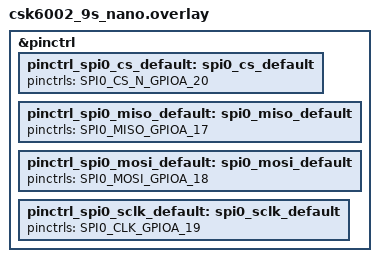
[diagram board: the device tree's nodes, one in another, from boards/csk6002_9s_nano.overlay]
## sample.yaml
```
tests:
  sample.board.csk6.driver.spi_master:
    platform_allow: csk6011a_nano
    tags: csk6
    harness: console
    timeout: 10
    harness_config:
      type: one_line
      regex:
        - "spi master sending data ..."
```

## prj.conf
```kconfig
CONFIG_GPIO=y
CONFIG_SPI=y
CONFIG_HEAP_MEM_POOL_SIZE=10240
CONFIG_LOG=y
```

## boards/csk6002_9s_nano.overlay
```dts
&pinctrl{
            /* SPIC alternate function */
            pinctrl_spi0_cs_default: spi0_cs_default{
                    pinctrls = <SPI0_CS_N_GPIOA_20>;
            };

            pinctrl_spi0_miso_default: spi0_miso_default{
                    pinctrls = <SPI0_MISO_GPIOA_17>;
            };

            pinctrl_spi0_mosi_default: spi0_mosi_default{
                    pinctrls = <SPI0_MOSI_GPIOA_18>;
            };

            pinctrl_spi0_sclk_default: spi0_sclk_default{
                    pinctrls = <SPI0_CLK_GPIOA_19>;
            };
            
};
```

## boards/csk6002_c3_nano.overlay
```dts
&csk6002_c3_nano_pinctrl{
            /* SPIC alternate function */
            pinctrl_spi0_cs_default: spi0_cs_default{
                    pinctrls = <SPI0_CS_N_GPIOA_20>;
            };

            pinctrl_spi0_miso_default: spi0_miso_default{
                    pinctrls = <SPI0_MISO_GPIOA_17>;
            };

            pinctrl_spi0_mosi_default: spi0_mosi_default{
                    pinctrls = <SPI0_MOSI_GPIOA_18>;
            };

            pinctrl_spi0_sclk_default: spi0_sclk_default{
                    pinctrls = <SPI0_CLK_GPIOA_19>;
            };
            
};
```

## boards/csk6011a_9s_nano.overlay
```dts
&csk6011a_9s_nano_pinctrl{
            /* SPIC alternate function */
            pinctrl_spi0_cs_default: spi0_cs_default{
                    pinctrls = <SPI0_CS_N_GPIOA_20>;
            };

            pinctrl_spi0_miso_default: spi0_miso_default{
                    pinctrls = <SPI0_MISO_GPIOA_17>;
            };

            pinctrl_spi0_mosi_default: spi0_mosi_default{
                    pinctrls = <SPI0_MOSI_GPIOA_18>;
            };

            pinctrl_spi0_sclk_default: spi0_sclk_default{
                    pinctrls = <SPI0_CLK_GPIOA_19>;
            };
            
};
```

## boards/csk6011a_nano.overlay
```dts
/*
 * Copyright (c) 2023 Anhui(Shenzhen) Listenai Co., Ltd.
 *
 * SPDX-License-Identifier: Apache-2.0
 */

&pinctrl {
	/* SPIC alternate function */
	pinctrl_spi0_cs_default: spi0_cs_default{
		pinctrls = <SPI0_CS_N_GPIOA_20>;
	};

	pinctrl_spi0_miso_default: spi0_miso_default{
		pinctrls = <SPI0_MISO_GPIOA_17>;
	};

	pinctrl_spi0_mosi_default: spi0_mosi_default{
		pinctrls = <SPI0_MOSI_GPIOA_18>;
	};

	pinctrl_spi0_sclk_default: spi0_sclk_default{
		pinctrls = <SPI0_CLK_GPIOA_19>;
	};

};
```

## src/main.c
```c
/*
 * Copyright (c) 2023 Anhui(Shenzhen) Listenai Co., Ltd.
 *
 * SPDX-License-Identifier: Apache-2.0
 */

#include <errno.h>
#include <string.h>

#include <device.h>
#include <drivers/spi.h>
#include <kernel.h>
#include <sys/printk.h>
#include <zephyr.h>

#define UINT8_MAX_NUM (0xff)

void main(void)
{
	printk("spi master example\n");
	const struct device *spi;
	spi = DEVICE_DT_GET(DT_NODELABEL(spi0));
	if (!device_is_ready(spi)) {
		printk("SPI device %s is not ready\n", spi->name);
		return;
	}

	struct spi_config spi_cfg = {0};
	/* spi master 8bit, LSB first*/
	spi_cfg.operation = SPI_WORD_SET(8) | SPI_OP_MODE_MASTER | SPI_TRANSFER_LSB;
	spi_cfg.frequency = 10 * 1000000UL;

#ifdef CONFIG_SPI_SOFT_GPIO_CS_ENABLE
	const struct spi_cs_control spi_cs_ctrl = {
		.gpio_dev = DEVICE_DT_GET(DT_NODELABEL(gpio0)),
		.gpio_pin = 20,
		.gpio_dt_flags = GPIO_ACTIVE_LOW, /* Invert gpio active level logic */
		.delay = 5 /* Delay 5us microseconds to wait before starting the */
			   /* transmission and before releasing the CS line */
	};
	spi_cfg.cs = &spi_cs_ctrl;
#endif

	/* Make spi transaction package buffers */
	const int tx_package_num = 10;
	struct spi_buf *tx_package = k_calloc(tx_package_num, sizeof(struct spi_buf));
	if (tx_package == NULL) {
		printk("tx_package calloc failed\n");
		return;
	}
	struct spi_buf_set tx_set;

	for (int tx_count = 0; tx_count < tx_package_num; tx_count++) {
		uint8_t *temp_buf = k_calloc(UINT8_MAX_NUM, sizeof(uint8_t));
		if (temp_buf == NULL) {
			printk("temp_buf calloc failed\n");
			return;
		}

		for (int num = 0; num < UINT8_MAX_NUM; num++) {
			if (tx_count % 2) {
				temp_buf[num] = UINT8_MAX_NUM - num;
			} else {
				temp_buf[num] = num;
			}
		}
		tx_package[tx_count].len = UINT8_MAX_NUM;
		tx_package[tx_count].buf = temp_buf;
	}
	tx_set.buffers = tx_package;
	tx_set.count = tx_package_num;

	while (1) {
		printk("spi master sending data ...\n");
		spi_write(spi, &spi_cfg, &tx_set);
		k_msleep(1000);
	}
}
```
